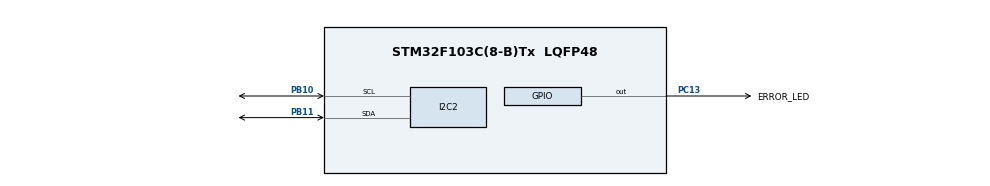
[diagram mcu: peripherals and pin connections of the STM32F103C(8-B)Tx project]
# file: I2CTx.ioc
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Mcu.Family=STM32F1
Mcu.Name=STM32F103C(8-B)Tx
Mcu.Package=LQFP48
NVIC.PriorityGroup=NVIC_PRIORITYGROUP_4
PB10.Mode=I2C
PB10.Signal=I2C2_SCL
PB11.Mode=I2C
PB11.Signal=I2C2_SDA
PC13-TAMPER-RTC.GPIO_Label=ERROR_LED
PC13-TAMPER-RTC.Signal=GPIO_Output
ProjectManager.HeapSize=0x200
ProjectManager.StackSize=0x400
ProjectManager.TargetToolchain=STM32CubeIDE
RCC.APB1Freq_Value=8000000
RCC.APB2Freq_Value=8000000
board=custom

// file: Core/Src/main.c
/* USER CODE BEGIN Header */
/**
  ******************************************************************************
  * @file           : main.c
  * @brief          : Main program body
  ******************************************************************************
  * @attention
  *
  * Copyright (c) 2023 STMicroelectronics.
  * All rights reserved.
  *
  * This software is licensed under terms that can be found in the LICENSE file
  * in the root directory of this software component.
  * If no LICENSE file comes with this software, it is provided AS-IS.
  *
  ******************************************************************************
  */
/* USER CODE END Header */
#include "main.h"

/* USER CODE BEGIN Includes */
#include <stdbool.h>

/* USER CODE END Includes */

I2C_HandleTypeDef hi2c2;

/* USER CODE BEGIN PV */
uint8_t		TX_Buffer[10] = {0x02, 0xCB, 0xAC, 0xBB, 0xCC, 0xDD, 0xAB, 0xAC,
			0xAD, 0xBA};
bool		IsTransferDone = true;
/* USER CODE END PV */

void	SystemClock_Config(void);
static void	MX_GPIO_Init(void);
static void	MX_I2C2_Init(void);

int	main(void)
{

	/* MCU Configuration--------------------------------------------------------*/

	/* Reset of all peripherals,
		Initializes the Flash interface and the Systick. */
	HAL_Init();

	/* Configure the system clock */
	SystemClock_Config();

	/* Initialize all configured peripherals */
	MX_GPIO_Init();
	MX_I2C2_Init();

	/* Infinite loop */
	/* USER CODE BEGIN WHILE */
	while (HAL_I2C_IsDeviceReady(&hi2c2, 2, 1, HAL_MAX_DELAY) != HAL_OK)
	{
		for (int i = 0; i < 15; i++)
		{
			HAL_GPIO_WritePin(ERROR_LED_GPIO_Port, ERROR_LED_Pin,
					GPIO_PIN_RESET);
			HAL_Delay(50);
			HAL_GPIO_WritePin(ERROR_LED_GPIO_Port, ERROR_LED_Pin,
					GPIO_PIN_SET);
			HAL_Delay(50);
		}
	}

	HAL_GPIO_WritePin(ERROR_LED_GPIO_Port, ERROR_LED_Pin, GPIO_PIN_RESET);

	while (1)
	{
		/* USER CODE END WHILE */

		/* USER CODE BEGIN 3 */

		for (int i = 0; i < 100; i++)
		{
			HAL_Delay(10);
			TX_Buffer[0] = i;
			HAL_I2C_Master_Transmit(&hi2c2, 2, TX_Buffer, 10, HAL_MAX_DELAY);
		}
	}
}
/* USER CODE END 3 */

void	SystemClock_Config(void)
{
	RCC_OscInitTypeDef RCC_OscInitStruct = {0};
	RCC_ClkInitTypeDef RCC_ClkInitStruct = {0};

	/** Initializes the RCC Oscillators according to the specified parameters
  * in the RCC_OscInitTypeDef structure.
  */
	RCC_OscInitStruct.OscillatorType = RCC_OSCILLATORTYPE_HSI;
	RCC_OscInitStruct.HSIState = RCC_HSI_ON;
	RCC_OscInitStruct.HSICalibrationValue = RCC_HSICALIBRATION_DEFAULT;
	RCC_OscInitStruct.PLL.PLLState = RCC_PLL_NONE;
	if (HAL_RCC_OscConfig(&RCC_OscInitStruct) != HAL_OK)
	{
		Error_Handler();
	}

	/** Initializes the CPU, AHB and APB buses clocks
  */
	RCC_ClkInitStruct.ClockType = RCC_CLOCKTYPE_HCLK | RCC_CLOCKTYPE_SYSCLK | RCC_CLOCKTYPE_PCLK1 | RCC_CLOCKTYPE_PCLK2;
	RCC_ClkInitStruct.SYSCLKSource = RCC_SYSCLKSOURCE_HSI;
	RCC_ClkInitStruct.AHBCLKDivider = RCC_SYSCLK_DIV1;
	RCC_ClkInitStruct.APB1CLKDivider = RCC_HCLK_DIV1;
	RCC_ClkInitStruct.APB2CLKDivider = RCC_HCLK_DIV1;

	if (HAL_RCC_ClockConfig(&RCC_ClkInitStruct, FLASH_LATENCY_0) != HAL_OK)
	{
		Error_Handler();
	}
}

static void	MX_I2C2_Init(void)
{

	hi2c2.Instance = I2C2;
	hi2c2.Init.ClockSpeed = 100000;
	hi2c2.Init.DutyCycle = I2C_DUTYCYCLE_2;
	hi2c2.Init.OwnAddress1 = 0;
	hi2c2.Init.AddressingMode = I2C_ADDRESSINGMODE_7BIT;
	hi2c2.Init.DualAddressMode = I2C_DUALADDRESS_DISABLE;
	hi2c2.Init.OwnAddress2 = 0;
	hi2c2.Init.GeneralCallMode = I2C_GENERALCALL_DISABLE;
	hi2c2.Init.NoStretchMode = I2C_NOSTRETCH_DISABLE;
	if (HAL_I2C_Init(&hi2c2) != HAL_OK)
	{
		Error_Handler();
	}
}

static void	MX_GPIO_Init(void)
{
	GPIO_InitTypeDef GPIO_InitStruct = {0};

	/* GPIO Ports Clock Enable */
	__HAL_RCC_GPIOC_CLK_ENABLE();
	__HAL_RCC_GPIOB_CLK_ENABLE();

	/*Configure GPIO pin Output Level */
	HAL_GPIO_WritePin(ERROR_LED_GPIO_Port, ERROR_LED_Pin, GPIO_PIN_RESET);

	/*Configure GPIO pin : ERROR_LED_Pin */
	GPIO_InitStruct.Pin = ERROR_LED_Pin;
	GPIO_InitStruct.Mode = GPIO_MODE_OUTPUT_PP;
	GPIO_InitStruct.Pull = GPIO_NOPULL;
	GPIO_InitStruct.Speed = GPIO_SPEED_FREQ_LOW;
	HAL_GPIO_Init(ERROR_LED_GPIO_Port, &GPIO_InitStruct);
}

void	Error_Handler(void)
{
	/* USER CODE BEGIN Error_Handler_Debug */
	/* User can add his own implementation to report the HAL error return state */
	__disable_irq();
	// while (1)
	// {
	// }
	/* USER CODE END Error_Handler_Debug */
}

#ifdef USE_FULL_ASSERT
/**
  * @brief  Reports the name of the source file and the source line number
  *         where the assert_param error has occurred.
  * @param  file: pointer to the source file name
  * @param  line: assert_param error line source number
  * @retval None
  */
void	assert_failed(uint8_t *file, uint32_t line)
{
	/* USER CODE BEGIN 6 */
	/* User can add his own implementation to report the file name and line number,
     ex: printf("Wrong parameters value: file %s on line %d\r\n", file,
		line) */
	/* USER CODE END 6 */
}
#endif /* USE_FULL_ASSERT */
